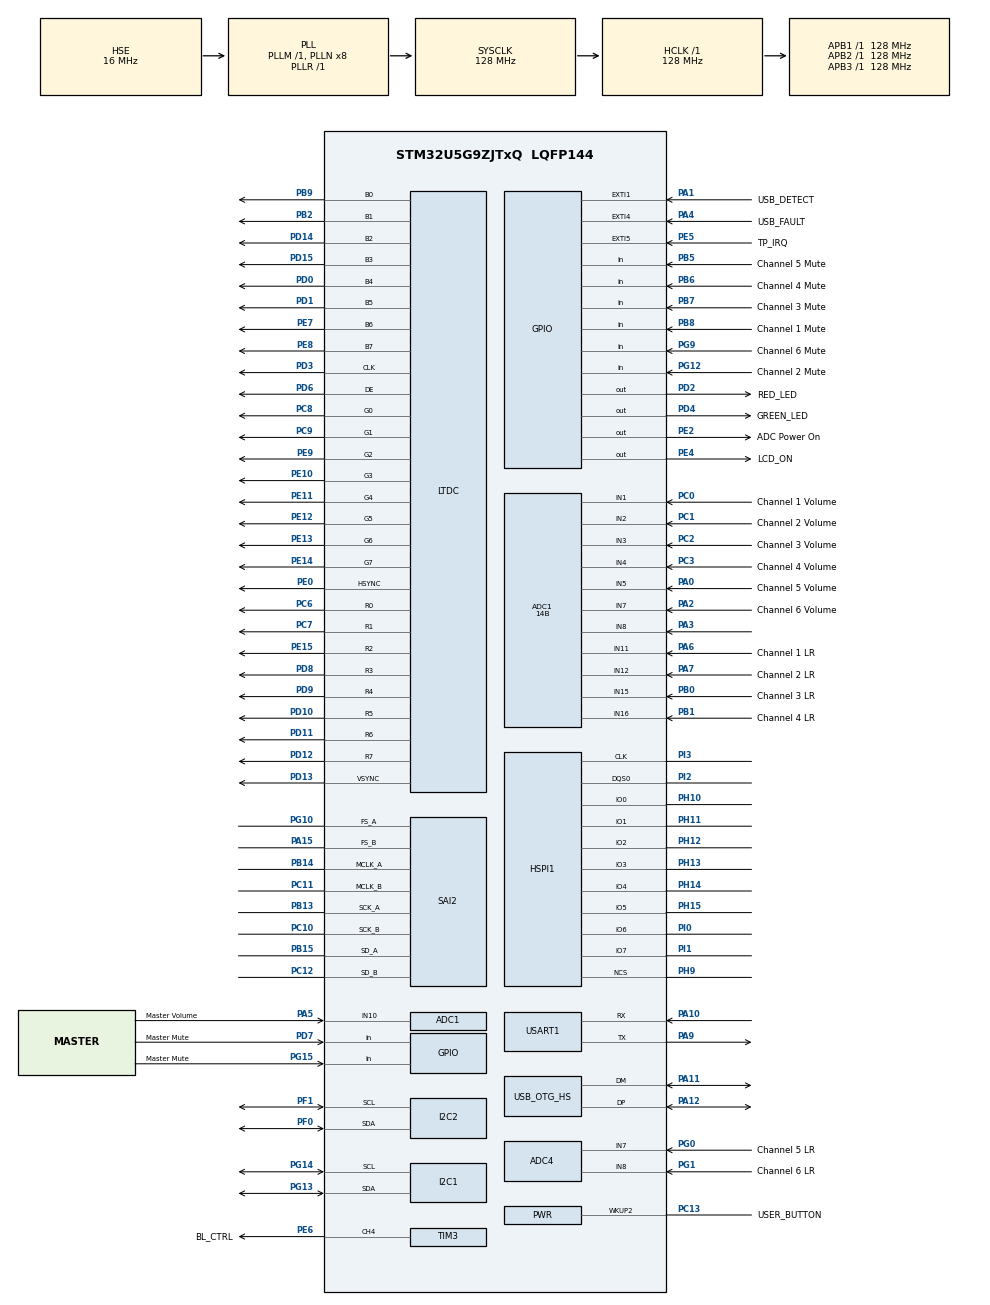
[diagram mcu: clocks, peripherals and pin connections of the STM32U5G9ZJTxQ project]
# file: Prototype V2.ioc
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ADC1.Channel-0\#ChannelRegularConversion=ADC_CHANNEL_1
ADC1.Channel-1\#ChannelRegularConversion=ADC_CHANNEL_2
ADC1.Channel-10\#ChannelRegularConversion=ADC_CHANNEL_15
ADC1.Channel-11\#ChannelRegularConversion=ADC_CHANNEL_16
ADC1.Channel-12\#ChannelRegularConversion=ADC_CHANNEL_TEMPSENSOR
ADC1.Channel-2\#ChannelRegularConversion=ADC_CHANNEL_3
ADC1.Channel-3\#ChannelRegularConversion=ADC_CHANNEL_4
ADC1.Channel-4\#ChannelRegularConversion=ADC_CHANNEL_5
ADC1.Channel-5\#ChannelRegularConversion=ADC_CHANNEL_7
ADC1.Channel-6\#ChannelRegularConversion=ADC_CHANNEL_8
ADC1.Channel-7\#ChannelRegularConversion=ADC_CHANNEL_10
ADC1.Channel-8\#ChannelRegularConversion=ADC_CHANNEL_11
ADC1.Channel-9\#ChannelRegularConversion=ADC_CHANNEL_12
ADC1.ContinuousConvMode=ENABLE
ADC1.ConversionDataManagement=ADC_CONVERSIONDATA_DMA_CIRCULAR
ADC1.DMAContinuousRequests=ENABLE
ADC1.ExternalTrigConv=ADC_EXTERNALTRIG_T15_TRGO
ADC1.LowPowerAutoWait=ENABLE
ADC1.MonitoredBy-0\#ChannelRegularConversion=__NULL
ADC1.MonitoredBy-1\#ChannelRegularConversion=__NULL
ADC1.MonitoredBy-10\#ChannelRegularConversion=__NULL
ADC1.MonitoredBy-11\#ChannelRegularConversion=__NULL
ADC1.MonitoredBy-12\#ChannelRegularConversion=__NULL
ADC1.MonitoredBy-2\#ChannelRegularConversion=__NULL
ADC1.MonitoredBy-3\#ChannelRegularConversion=__NULL
ADC1.MonitoredBy-4\#ChannelRegularConversion=__NULL
ADC1.MonitoredBy-5\#ChannelRegularConversion=__NULL
ADC1.MonitoredBy-6\#ChannelRegularConversion=__NULL
ADC1.MonitoredBy-7\#ChannelRegularConversion=__NULL
ADC1.MonitoredBy-8\#ChannelRegularConversion=__NULL
ADC1.MonitoredBy-9\#ChannelRegularConversion=__NULL
ADC1.NbrOfConversion=13
ADC1.NbrOfConversionFlag=1
ADC1.OffsetNumber-0\#ChannelRegularConversion=ADC_OFFSET_NONE
ADC1.OffsetNumber-1\#ChannelRegularConversion=ADC_OFFSET_NONE
ADC1.OffsetNumber-10\#ChannelRegularConversion=ADC_OFFSET_NONE
ADC1.OffsetNumber-11\#ChannelRegularConversion=ADC_OFFSET_NONE
ADC1.OffsetNumber-12\#ChannelRegularConversion=ADC_OFFSET_NONE
ADC1.OffsetNumber-2\#ChannelRegularConversion=ADC_OFFSET_NONE
ADC1.OffsetNumber-3\#ChannelRegularConversion=ADC_OFFSET_NONE
ADC1.OffsetNumber-4\#ChannelRegularConversion=ADC_OFFSET_NONE
ADC1.OffsetNumber-5\#ChannelRegularConversion=ADC_OFFSET_NONE
ADC1.OffsetNumber-6\#ChannelRegularConversion=ADC_OFFSET_NONE
ADC1.OffsetNumber-7\#ChannelRegularConversion=ADC_OFFSET_NONE
ADC1.OffsetNumber-8\#ChannelRegularConversion=ADC_OFFSET_NONE
ADC1.OffsetNumber-9\#ChannelRegularConversion=ADC_OFFSET_NONE
ADC1.Rank-0\#ChannelRegularConversion=1
ADC1.Rank-1\#ChannelRegularConversion=2
ADC1.Rank-10\#ChannelRegularConversion=11
ADC1.Rank-11\#ChannelRegularConversion=12
ADC1.Rank-12\#ChannelRegularConversion=13
ADC1.Rank-2\#ChannelRegularConversion=3
ADC1.Rank-3\#ChannelRegularConversion=4
ADC1.Rank-4\#ChannelRegularConversion=5
ADC1.Rank-5\#ChannelRegularConversion=6
ADC1.Rank-6\#ChannelRegularConversion=7
ADC1.Rank-7\#ChannelRegularConversion=8
ADC1.Rank-8\#ChannelRegularConversion=9
ADC1.Rank-9\#ChannelRegularConversion=10
ADC1.Resolution=ADC_RESOLUTION_14B
ADC1.SamplingTime-0\#ChannelRegularConversion=ADC_SAMPLETIME_5CYCLE
ADC1.SamplingTime-1\#ChannelRegularConversion=ADC_SAMPLETIME_5CYCLE
ADC1.SamplingTime-10\#ChannelRegularConversion=ADC_SAMPLETIME_5CYCLE
ADC1.SamplingTime-11\#ChannelRegularConversion=ADC_SAMPLETIME_5CYCLE
ADC1.SamplingTime-12\#ChannelRegularConversion=ADC_SAMPLETIME_5CYCLE
ADC1.SamplingTime-2\#ChannelRegularConversion=ADC_SAMPLETIME_5CYCLE
ADC1.SamplingTime-3\#ChannelRegularConversion=ADC_SAMPLETIME_5CYCLE
ADC1.SamplingTime-4\#ChannelRegularConversion=ADC_SAMPLETIME_5CYCLE
ADC1.SamplingTime-5\#ChannelRegularConversion=ADC_SAMPLETIME_5CYCLE
ADC1.SamplingTime-6\#ChannelRegularConversion=ADC_SAMPLETIME_5CYCLE
ADC1.SamplingTime-7\#ChannelRegularConversion=ADC_SAMPLETIME_5CYCLE
ADC1.SamplingTime-8\#ChannelRegularConversion=ADC_SAMPLETIME_5CYCLE
ADC1.SamplingTime-9\#ChannelRegularConversion=ADC_SAMPLETIME_5CYCLE
ADC1.master=1
ADC4.Channel-0\#ChannelRegularConversion=ADC_CHANNEL_7
ADC4.Channel-1\#ChannelRegularConversion=ADC_CHANNEL_8
ADC4.ContinuousConvMode=ENABLE
ADC4.DMAContinuousRequests=ENABLE
ADC4.NbrOfConversion=2
ADC4.NbrOfConversionFlag=1
ADC4.OffsetNumber-0\#ChannelRegularConversion=ADC_OFFSET_NONE
ADC4.OffsetNumber-1\#ChannelRegularConversion=ADC_OFFSET_NONE
ADC4.Rank-0\#ChannelRegularConversion=1
ADC4.Rank-1\#ChannelRegularConversion=2
ADC4.RankArg-0\#ChannelRegularConversion=ADC4_REGULAR_RANK_1
ADC4.RankArg-1\#ChannelRegularConversion=ADC4_REGULAR_RANK_2
ADC4.SamplingTime-0\#ChannelRegularConversion=ADC4_SAMPLINGTIME_COMMON_1
ADC4.SamplingTime-1\#ChannelRegularConversion=ADC4_SAMPLINGTIME_COMMON_1
ADC4.SelectedChannel=ADC_CHANNEL_7|ADC_CHANNEL_8
CORTEX_M33_NS.userName=CORTEX_M33
DMA2D.ColorMode=DMA2D_OUTPUT_RGB888
DMA2D.Mode=DMA2D_M2M
GPDMA1.CIRCULARMODE_GPDMACH0=ENABLE
GPDMA1.CIRCULARMODE_GPDMACH1=ENABLE
GPDMA1.CIRCULARMODE_GPDMACH3=ENABLE
GPDMA1.DATAHANDLING_GPDMACH3=NONE
GPDMA1.DESTDATAWIDTH_GPDMACH0=DMA_DEST_DATAWIDTH_HALFWORD
GPDMA1.DESTDATAWIDTH_GPDMACH1=DMA_DEST_DATAWIDTH_WORD
GPDMA1.DESTDATAWIDTH_GPDMACH2=DMA_DEST_DATAWIDTH_HALFWORD
GPDMA1.DESTDATAWIDTH_GPDMACH3=DMA_DEST_DATAWIDTH_WORD
GPDMA1.DESTINC_GPDMACH0=DMA_DINC_INCREMENTED
GPDMA1.DESTINC_GPDMACH1=DMA_DINC_INCREMENTED
GPDMA1.DESTINC_GPDMACH2=DMA_DINC_INCREMENTED
GPDMA1.DIRECTION_GPDMACH3=DMA_MEMORY_TO_PERIPH
GPDMA1.DMAHANDLE_GPDMACH3=hdmatx
GPDMA1.IPHANDLE_GPDMACH0-SIMPLEREQUEST_GPDMACH0=__NULL
GPDMA1.IPHANDLE_GPDMACH1-SIMPLEREQUEST_GPDMACH1=__NULL
GPDMA1.IPHANDLE_GPDMACH2-SIMPLEREQUEST_GPDMACH2=__NULL
GPDMA1.IPHANDLE_GPDMACH3-SIMPLEREQUEST_GPDMACH3=__NULL
GPDMA1.PRIORITY_LL_CIRCULAR_GPDMACH1=DMA_LOW_PRIORITY_MID_WEIGHT
GPDMA1.PRIORITY_LL_CIRCULAR_GPDMACH3=DMA_LOW_PRIORITY_HIGH_WEIGHT
GPDMA1.REQUEST_GPDMACH0=GPDMA1_REQUEST_ADC1
GPDMA1.REQUEST_GPDMACH1=GPDMA1_REQUEST_SAI2_B
GPDMA1.REQUEST_GPDMACH2=GPDMA1_REQUEST_ADC4
GPDMA1.REQUEST_GPDMACH3=GPDMA1_REQUEST_SAI2_A
GPDMA1.SRCDATAWIDTH_GPDMACH0=DMA_SRC_DATAWIDTH_HALFWORD
GPDMA1.SRCDATAWIDTH_GPDMACH1=DMA_SRC_DATAWIDTH_WORD
GPDMA1.SRCDATAWIDTH_GPDMACH2=DMA_SRC_DATAWIDTH_HALFWORD
GPDMA1.SRCDATAWIDTH_GPDMACH3=DMA_SRC_DATAWIDTH_WORD
GPDMA1.SRCINC_GPDMACH1=DMA_SINC_FIXED
GPDMA1.SRCINC_GPDMACH3=DMA_SINC_INCREMENTED
GPDMA1.TRANSFERALLOCATEDPORTDEST_GPDMACH0=DMA_DEST_ALLOCATED_PORT1
GPDMA1.TRIGGERPOLARITY_GPDMACH0=DMA_TRIG_POLARITY_RISING
GPDMA1.TRIGGERSELECTION_GPDMACH0=GPDMA1_TRIGGER_TIM15_TRGO
HSPI1.ChipSelectBoundary=HAL_XSPI_BONDARYOF_NONE
HSPI1.ChipSelectHighTimeCycle=2
HSPI1.FifoThresholdByte=4
HSPI1.MemorySize=HAL_XSPI_SIZE_1GB
HSPI1.MemoryType=HAL_XSPI_MEMTYPE_MACRONIX
I2C1.Timing=0x20A0C4DF
I2C2.Timing=0x20A0C4DF
LTDC.ActiveH=480
LTDC.ActiveW=800
LTDC.Alpha_L0=255
LTDC.BlendingFactor1_L0=LTDC_BLENDING_FACTOR1_PAxCA
LTDC.BlendingFactor2_L0=LTDC_BLENDING_FACTOR2_PAxCA
LTDC.HBP=8
LTDC.HFP=8
LTDC.HSync=4
LTDC.Layers=0
LTDC.PCPolarity=LTDC_PCPOLARITY_IPC
LTDC.PixelFormat_L0=LTDC_PIXEL_FORMAT_RGB888
LTDC.VBP=8
LTDC.VFP=8
LTDC.WindowX1_L0=800
LTDC.WindowY1_L0=480
Mcu.Family=STM32U5
Mcu.Name=STM32U5G9ZJTxQ
Mcu.Package=LQFP144
NVIC.ADC1_2_IRQn=true\:0\:0\:false\:false\:true\:true\:true\:true
NVIC.EXTI1_IRQn=true\:0\:0\:false\:false\:true\:true\:true\:true
NVIC.EXTI4_IRQn=true\:0\:0\:false\:false\:true\:true\:true\:true
NVIC.EXTI5_IRQn=true\:0\:0\:false\:false\:true\:true\:true\:true
NVIC.GPDMA1_Channel0_IRQn=true\:0\:0\:false\:false\:true\:false\:true\:true
NVIC.GPDMA1_Channel1_IRQn=true\:0\:0\:false\:false\:true\:false\:true\:true
NVIC.GPDMA1_Channel2_IRQn=true\:0\:0\:false\:false\:true\:false\:true\:true
NVIC.GPDMA1_Channel3_IRQn=true\:0\:0\:false\:false\:true\:false\:true\:true
NVIC.I2C2_ER_IRQn=true\:0\:0\:false\:false\:true\:true\:true\:false
NVIC.I2C2_EV_IRQn=true\:0\:0\:false\:false\:true\:true\:true\:true
NVIC.LTDC_IRQn=true\:0\:0\:false\:false\:true\:true\:true\:true
NVIC.PriorityGroup=NVIC_PRIORITYGROUP_4
NVIC.USART1_IRQn=true\:0\:0\:false\:false\:true\:true\:true\:true
PA0.GPIO_Label=Channel 5 Volume
PA0.Mode=IN5-Single-Ended
PA0.Signal=ADC1_IN5
PA1.GPIO_Label=USB_DETECT
PA1.GPIO_ModeDefaultEXTI=GPIO_MODE_IT_RISING_FALLING
PA1.Signal=GPXTI1
PA10.Mode=Asynchronous
PA10.Signal=USART1_RX
PA11.Mode=Internal_Phy_Device
PA11.Signal=USB_OTG_HS_DM
PA12.Mode=Internal_Phy_Device
PA12.Signal=USB_OTG_HS_DP
PA13\ (JTMS/SWDIO).Mode=Trace_Asynchronous_SW
PA13\ (JTMS/SWDIO).Signal=DEBUG_JTMS-SWDIO
PA14\ (JTCK/SWCLK).Mode=Trace_Asynchronous_SW
PA14\ (JTCK/SWCLK).Signal=DEBUG_JTCK-SWCLK
PA15\ (JTDI).GPIO_Speed=GPIO_SPEED_FREQ_VERY_HIGH
PA15\ (JTDI).Mode=SAI_B_MasterWithClock
PA15\ (JTDI).Signal=SAI2_FS_B
PA2.GPIO_Label=Channel 6 Volume
PA2.Mode=IN7-Single-Ended
PA2.Signal=ADC1_IN7
PA3.Mode=IN8-Single-Ended
PA3.Signal=ADC1_IN8
PA4.GPIO_Label=USB_FAULT
PA4.GPIO_ModeDefaultEXTI=GPIO_MODE_IT_FALLING
PA4.GPIO_PuPd=GPIO_PULLUP
PA4.Signal=GPXTI4
PA5.GPIO_Label=Master Volume
PA5.Mode=IN10-Single-Ended
PA5.Signal=ADC1_IN10
PA6.GPIO_Label=Channel 1 LR
PA6.Mode=IN11-Single-Ended
PA6.Signal=ADC1_IN11
PA7.GPIO_Label=Channel 2 LR
PA7.Mode=IN12-Single-Ended
PA7.Signal=ADC1_IN12
PA9.Mode=Asynchronous
PA9.Signal=USART1_TX
PB0.GPIO_Label=Channel 3 LR
PB0.Mode=IN15-Single-Ended
PB0.Signal=ADC1_IN15
PB1.GPIO_Label=Channel 4 LR
PB1.Mode=IN16-Single-Ended
PB1.Signal=ADC1_IN16
PB13.Mode=SAI_A_MasterWithClock
PB13.Signal=SAI2_SCK_A
PB14.GPIO_Speed=GPIO_SPEED_FREQ_VERY_HIGH
PB14.Mode=SAI_A_MasterWithClock
PB14.Signal=SAI2_MCLK_A
PB15.Mode=SAI_A_MasterWithClock
PB15.Signal=SAI2_SD_A
PB2.Mode=RGB888
PB2.Signal=LTDC_B1
PB3\ (JTDO/TRACESWO).Mode=Trace_Asynchronous_SW
PB3\ (JTDO/TRACESWO).Signal=DEBUG_JTDO-SWO
PB5.GPIO_Label=Channel 5 Mute
PB5.Signal=GPIO_Input
PB6.GPIO_Label=Channel 4 Mute
PB6.Signal=GPIO_Input
PB7.GPIO_Label=Channel 3 Mute
PB7.Signal=GPIO_Input
PB8.GPIO_Label=Channel 1 Mute
PB8.Signal=GPIO_Input
PB9.Mode=RGB888
PB9.Signal=LTDC_B0
PC0.GPIO_Label=Channel 1 Volume
PC0.Mode=IN1-Single-Ended
PC0.Signal=ADC1_IN1
PC1.GPIO_Label=Channel 2 Volume
PC1.Mode=IN2-Single-Ended
PC1.Signal=ADC1_IN2
PC10.GPIO_PuPd=GPIO_NOPULL
PC10.GPIO_Speed=GPIO_SPEED_FREQ_VERY_HIGH
PC10.Mode=SAI_B_MasterWithClock
PC10.Signal=SAI2_SCK_B
PC11.Mode=SAI_B_MasterWithClock
PC11.Signal=SAI2_MCLK_B
PC12.Mode=SAI_B_MasterWithClock
PC12.Signal=SAI2_SD_B
PC13.GPIO_Label=USER_BUTTON
PC13.Mode=WakeUp2
PC13.Signal=PWR_WKUP2
PC14-OSC32_IN\ (PC14).Mode=LSE-External-Oscillator
PC14-OSC32_IN\ (PC14).Signal=RCC_OSC32_IN
PC15-OSC32_OUT\ (PC15).Mode=LSE-External-Oscillator
PC15-OSC32_OUT\ (PC15).Signal=RCC_OSC32_OUT
PC2.GPIO_Label=Channel 3 Volume
PC2.Mode=IN3-Single-Ended
PC2.Signal=ADC1_IN3
PC3.GPIO_Label=Channel 4 Volume
PC3.Mode=IN4-Single-Ended
PC3.Signal=ADC1_IN4
PC6.Mode=RGB888
PC6.Signal=LTDC_R0
PC7.Mode=RGB888
PC7.Signal=LTDC_R1
PC8.Mode=RGB888
PC8.Signal=LTDC_G0
PC9.Mode=RGB888
PC9.Signal=LTDC_G1
PD0.Mode=RGB888
PD0.Signal=LTDC_B4
PD1.Mode=RGB888
PD1.Signal=LTDC_B5
PD10.Mode=RGB888
PD10.Signal=LTDC_R5
PD11.Mode=RGB888
PD11.Signal=LTDC_R6
PD12.Mode=RGB888
PD12.Signal=LTDC_R7
PD13.Mode=RGB888
PD13.Signal=LTDC_VSYNC
PD14.Mode=RGB888
PD14.Signal=LTDC_B2
PD15.Mode=RGB888
PD15.Signal=LTDC_B3
PD2.GPIO_Label=RED_LED
PD2.Signal=GPIO_Output
PD3.Mode=RGB888
PD3.Signal=LTDC_CLK
PD4.GPIO_Label=GREEN_LED
PD4.Signal=GPIO_Output
PD6.Mode=RGB888
PD6.Signal=LTDC_DE
PD7.GPIO_Label=Master Mute
PD7.Signal=GPIO_Input
PD8.Mode=RGB888
PD8.Signal=LTDC_R3
PD9.Mode=RGB888
PD9.Signal=LTDC_R4
PE0.Mode=RGB888
PE0.Signal=LTDC_HSYNC
PE10.Mode=RGB888
PE10.Signal=LTDC_G3
PE11.Mode=RGB888
PE11.Signal=LTDC_G4
PE12.Mode=RGB888
PE12.Signal=LTDC_G5
PE13.Mode=RGB888
PE13.Signal=LTDC_G6
PE14.Mode=RGB888
PE14.Signal=LTDC_G7
PE15.Mode=RGB888
PE15.Signal=LTDC_R2
PE2.GPIO_Label=ADC Power On
PE2.Signal=GPIO_Output
PE4.GPIO_Label=LCD_ON
PE4.PinState=GPIO_PIN_SET
PE4.Signal=GPIO_Output
PE5.GPIO_Label=TP_IRQ
PE5.Signal=GPXTI5
PE6.GPIO_Label=BL_CTRL
PE6.Signal=S_TIM3_CH4
PE7.Mode=RGB888
PE7.Signal=LTDC_B6
PE8.Mode=RGB888
PE8.Signal=LTDC_B7
PE9.Mode=RGB888
PE9.Signal=LTDC_G2
PF0.Mode=I2C
PF0.Signal=I2C2_SDA
PF1.Mode=I2C
PF1.Signal=I2C2_SCL
PG0.GPIO_Label=Channel 5 LR
PG0.Mode=IN7
PG0.Signal=ADC4_IN7
PG1.GPIO_Label=Channel 6 LR
PG1.Mode=IN8
PG1.Signal=ADC4_IN8
PG10.Mode=SAI_A_MasterWithClock
PG10.Signal=SAI2_FS_A
PG12.GPIO_Label=Channel 2 Mute
PG12.Signal=GPIO_Input
PG13.Mode=I2C
PG13.Signal=I2C1_SDA
PG14.Mode=I2C
PG14.Signal=I2C1_SCL
PG15.GPIO_Label=Master Mute
PG15.Signal=GPIO_Input
PG9.GPIO_Label=Channel 6 Mute
PG9.Signal=GPIO_Input
PH0-OSC_IN\ (PH0).Mode=HSE-External-Oscillator
PH0-OSC_IN\ (PH0).Signal=RCC_OSC_IN
PH1-OSC_OUT\ (PH1).Mode=HSE-External-Oscillator
PH1-OSC_OUT\ (PH1).Signal=RCC_OSC_OUT
PH10.Mode=octo_mode
PH10.Signal=HSPI1_IO0
PH11.Mode=octo_mode
PH11.Signal=HSPI1_IO1
PH12.Mode=octo_mode
PH12.Signal=HSPI1_IO2
PH13.Mode=octo_mode
PH13.Signal=HSPI1_IO3
PH14.Mode=octo_mode
PH14.Signal=HSPI1_IO4
PH15.Mode=octo_mode
PH15.Signal=HSPI1_IO5
PH9.Mode=octo_mode
PH9.Signal=HSPI1_NCS
PI0.Mode=octo_mode
PI0.Signal=HSPI1_IO6
PI1.Mode=octo_mode
PI1.Signal=HSPI1_IO7
PI2.Mode=octo_mode
PI2.Signal=HSPI1_DQS0
PI3.Mode=octo_mode
PI3.Signal=HSPI1_CLK
PWR.PowerMode=PWR_SMPS_SUPPLY
ProjectManager.HeapSize=0x400
ProjectManager.StackSize=0x800
ProjectManager.TargetToolchain=STM32CubeIDE
RCC.ADCFreq_Value=16000000
RCC.AHBFreq_Value=128000000
RCC.APB1Freq_Value=128000000
RCC.APB1TimFreq_Value=128000000
RCC.APB2Freq_Value=128000000
RCC.APB2TimFreq_Value=128000000
RCC.APB3Freq_Value=128000000
RCC.CortexFreq_Value=128000000
RCC.EPOD_VALUE=16000000
RCC.HCLKFreq_Value=128000000
RCC.HSE_VALUE=16000000
RCC.HSI48_VALUE=48000000
RCC.HSI_VALUE=16000000
RCC.HSPICLockSelection=RCC_HSPICLKSOURCE_PLL2
RCC.LSIDIV_VALUE=32000
RCC.LTDCCLockSelection=RCC_LTDCCLKSOURCE_PLL3
RCC.MSIClockRange=RCC_MSIRANGE_0
RCC.MSI_VALUE=48000000
RCC.PLL1P=8
RCC.PLL1R=1
RCC.PLL2FRACN=4096
RCC.PLL2N=12
RCC.PLL2Q=3
RCC.PLL2R=4
RCC.PLL2Source=RCC_PLLSOURCE_HSE
RCC.PLL3FRACN=0
RCC.PLL3M=4
RCC.PLL3N=50
RCC.PLL3R=8
RCC.PLL3Source=RCC_PLLSOURCE_HSE
RCC.PLLFRACN=0
RCC.PLLN=8
RCC.PLLSourceVirtual=RCC_PLLSOURCE_HSE
RCC.RTCClockSelection=RCC_RTCCLKSOURCE_LSE
RCC.SYSCLKFreq_VALUE=128000000
RCC.SYSCLKSource=RCC_SYSCLKSOURCE_PLLCLK
RCC.VCOOutputFreq_Value=128000000
SAI2.AudioFrequency-SAI_A_MasterWithClock=SAI_AUDIO_FREQUENCY_96K
SAI2.AudioFrequency-SAI_B_MasterWithClock=SAI_AUDIO_FREQUENCY_96K
SAI2.AudioMode-SAI_B_MasterWithClock=SAI_MODEMASTER_RX
SAI2.BasicDataSize-SAI_A_MasterWithClock=SAI_PROTOCOL_DATASIZE_24BIT
SAI2.BasicDataSize-SAI_B_MasterWithClock=SAI_PROTOCOL_DATASIZE_24BIT
SAI2.BasicProtocol-SAI_A_MasterWithClock=SAI_I2S_MSBJUSTIFIED
SAI2.BasicSlotNumber-SAI_B_MasterWithClock=8
SAI2.ErrorAudioFreq-SAI_A_MasterWithClock=1.72 %
SAI2.ErrorAudioFreq-SAI_B_MasterWithClock=1.72 %
SAI2.FIFOThreshold-SAI_A_MasterWithClock=SAI_FIFOTHRESHOLD_EMPTY
SAI2.FIFOThreshold-SAI_B_MasterWithClock=SAI_FIFOTHRESHOLD_HF
SAI2.InitProtocol-SAI_A_MasterWithClock=Enable
SAI2.InitProtocol-SAI_B_MasterWithClock=Enable
SAI2.Instance-SAI_A_MasterWithClock=SAI$Index_Block_A
SAI2.Instance-SAI_B_MasterWithClock=SAI$Index_Block_B
SAI2.MckOutput-SAI_A_MasterWithClock=SAI_MCK_OUTPUT_ENABLE
SAI2.MckOutput-SAI_B_MasterWithClock=SAI_MCK_OUTPUT_ENABLE
SAI2.RealAudioFreq-SAI_A_MasterWithClock=97.656 KHz
SAI2.RealAudioFreq-SAI_B_MasterWithClock=97.656 KHz
SAI2.TriState-SAI_A_MasterWithClock=SAI_OUTPUT_RELEASED
SAI2.VirtualMode-SAI_A_MasterWithClock=VM_MASTER
SAI2.VirtualMode-SAI_B_MasterWithClock=VM_MASTER
SAI2.VirtualProtocol-SAI_A_BASIC=VM_BASIC_PROTOCOL
SAI2.VirtualProtocol-SAI_B_BASIC=VM_BASIC_PROTOCOL
SH.S_TIM3_CH4.0=TIM3_CH4,PWM Generation4 CH4
TIM15.PeriodNoDither=49
TIM15.Prescaler=26
TIM15.TIM_MasterOutputTrigger=TIM_TRGO_UPDATE
TIM3.Channel-PWM\ Generation4\ CH4=TIM_CHANNEL_4
TIM3.OC4Preload_PWM=DISABLE
TIM3.PeriodNoDither=100
TIM3.Prescaler=160
TIM3.PulseNoDither_4=75
USART1.VirtualMode-Asynchronous=VM_ASYNC
USB_OTG_HS.VirtualMode=Device_HS
VP_ADC1_TempSens_Input.Mode=IN-TempSens
VP_DMA2D_VS_DMA2D.Mode=DMA2D_Activate
VP_GPDMA1_VS_GPDMACH0.Mode=SIMPLEREQUEST_GPDMACH0
VP_GPDMA1_VS_GPDMACH1.Mode=SIMPLEREQUEST_GPDMACH1
VP_GPDMA1_VS_GPDMACH2.Mode=SIMPLEREQUEST_GPDMACH2
VP_GPDMA1_VS_GPDMACH3.Mode=SIMPLEREQUEST_GPDMACH3
VP_ICACHE_VS_ICACHE.Mode=DirectMappedCache
VP_LPBAMQUEUE_VS_QUEUE.Mode=QUEUEMODE
VP_LPBAM_VS_SIG1.Mode=SmartRun
VP_LPBAM_VS_SIG4.Mode=LPDMA1
VP_MEMORYMAP_VS_MEMORYMAP.Mode=CurAppReg
VP_PWR_VS_LPOM.Mode=PowerOptimisation
VP_PWR_VS_SECSignals.Mode=Security/Privilege
VP_PWR_Vdda.Mode=isolationVdda
VP_RTC_VS_RTC_Activate.Mode=RTC_Enabled
VP_SAI2_VP_$IpInstance_SAIA_SAI_BASIC.Mode=SAI_A_BASIC
VP_SAI2_VP_$IpInstance_SAIB_SAI_BASIC.Mode=SAI_B_BASIC
VP_TIM15_VS_ClockSourceINT.Mode=Internal
board=STM32U5G9J-DK2

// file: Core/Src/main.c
/* USER CODE BEGIN Header */
/**
  ******************************************************************************
  * @file           : main.c
  * @brief          : Main program body
  ******************************************************************************
  * @attention
  *
  * Copyright (c) 2024 STMicroelectronics.
  * All rights reserved.
  *
  * This software is licensed under terms that can be found in the LICENSE file
  * in the root directory of this software component.
  * If no LICENSE file comes with this software, it is provided AS-IS.
  *
  ******************************************************************************
  */
/* USER CODE END Header */
#include "main.h"

/* USER CODE BEGIN Includes */
#include "math.h"
#include "stdbool.h"
/* USER CODE END Includes */

/* USER CODE BEGIN PD */
#define sampleSize 32 //System will capture specificed number of samples per channel
#define denoiseSize 1
#define gain 1
#define devAddress 0x90 //Device address of PCM6260, pre-shift
//TODO: Determine the actual array position of these values
#define c1Vol 0
#define c2Vol 1
#define c3Vol 2
#define c4Vol 3
#define c5Vol 4
#define c6Vol 5
#define masterVol 6
#define c1LR 7
#define c2LR 8
#define c3LR 9
#define c4LR 10
#define c5LR 11
#define c6LR 12

#define channelSettings 0xA6
/*
 * 7 - 0 = Microphone 1 = Line
 * 6-5 - 0d = analog differential 1d = analog single ended
 * 4 - 0d = A/C coupled 1d = D/C coupled
 * 3 - 0d low swing mode 1d high swing mode
 * 2-1 - 0d high snr 2d high cmrr
 * 0 0 - AGC disabled, 1 - AGC enabled
 */

//Struct defining a "Channel" object, which consists of a sample buffer, and various effect
//control parameters
struct channelStruct{
	uint32_t channelData[sampleSize];
	uint8_t channelNum;
	bool masterMute;
	float volume;
	float LRPan;
	bool reverbEnable;
	bool EQEnable;
	bool distortionEnable;
	float reverbStrength;
	float eqLevels[5];
	float distortionStrength;
};
/* USER CODE END PD */

/* USER CODE BEGIN PM */
#define DIM(a)	(sizeof(a)/sizeof(*a)) //Macro for determining correct TX/RX size
/* USER CODE END PM */

ADC_HandleTypeDef hadc1;
ADC_HandleTypeDef hadc4;
DMA_NodeTypeDef Node_GPDMA1_Channel0;
DMA_QListTypeDef List_GPDMA1_Channel0;
DMA_HandleTypeDef handle_GPDMA1_Channel0;
DMA_HandleTypeDef handle_GPDMA1_Channel2;

DMA2D_HandleTypeDef hdma2d;

XSPI_HandleTypeDef hxspi1;

I2C_HandleTypeDef hi2c1;
I2C_HandleTypeDef hi2c2;

LTDC_HandleTypeDef hltdc;

RTC_HandleTypeDef hrtc;

SAI_HandleTypeDef hsai_BlockA2;
SAI_HandleTypeDef hsai_BlockB2;
DMA_NodeTypeDef Node_GPDMA1_Channel3;
DMA_QListTypeDef List_GPDMA1_Channel3;
DMA_HandleTypeDef handle_GPDMA1_Channel3;
DMA_NodeTypeDef Node_GPDMA1_Channel1;
DMA_QListTypeDef List_GPDMA1_Channel1;
DMA_HandleTypeDef handle_GPDMA1_Channel1;

TIM_HandleTypeDef htim3;
TIM_HandleTypeDef htim15;

UART_HandleTypeDef huart1;

PCD_HandleTypeDef hpcd_USB_OTG_HS;

/* USER CODE BEGIN PV */

uint16_t adcGroup1[13] = {0}; //buffer for all ADC values connected to ADC1(volume and LR pots)
uint16_t adcGroup4[2] = {0}; //buffer for all ADC Values connected to ADC4(volume and LR pots)
uint32_t pcmData[sampleSize  * 8] = {0}; //Buffer for 8 channels of audio data
int32_t dacData[sampleSize * 2] = {0};
float ch1Vol = 0;

//contains all instructions for configuring PCM6260
static uint8_t pcm6260Config[][2] =
{
		{0x00, 0x00},//Set page to 0
		{0x02, 0x81},//Set to awake
		{0x28,0x10},//Settings reset
		{0x3C,channelSettings}, //config channels
		{0x46,channelSettings},
		{0x4B,channelSettings},
		{0x50,channelSettings},
		{0x55,channelSettings},
		{0x3B, 0x70}, //
		{0x73,0xFE}, //Enable Input Channels
		{0x74, 0xFE}, //Enable ASI output
		{0x3B, 0xF0}, //Config MicBias 9v
		{0x75, 0xE0} //enable Micbias, PLL
};

struct channelStruct channels[6] = {0}; //Creates a blank channelStruct array
/* USER CODE END PV */

void SystemClock_Config(void);
void PeriphCommonClock_Config(void);
static void SystemPower_Config(void);
static void MX_GPIO_Init(void);
static void MX_GPDMA1_Init(void);
static void MX_DMA2D_Init(void);
static void MX_HSPI1_Init(void);
static void MX_I2C2_Init(void);
static void MX_ICACHE_Init(void);
static void MX_LTDC_Init(void);
static void MX_RTC_Init(void);
static void MX_TIM3_Init(void);
static void MX_ADC1_Init(void);
static void MX_USART1_UART_Init(void);
static void MX_SAI2_Init(void);
static void MX_ADC4_Init(void);
static void MX_I2C1_Init(void);
static void MX_USB_OTG_HS_PCD_Init(void);
static void MX_TIM15_Init(void);
/* USER CODE BEGIN PFP */
static uint16_t getAverageADC(uint16_t);
/* USER CODE END PFP */

int main(void)
{

  /* MCU Configuration--------------------------------------------------------*/

  /* Reset of all peripherals, Initializes the Flash interface and the Systick. */
  HAL_Init();

  /* Configure the system clock */
  SystemClock_Config();

  /* Configure the peripherals common clocks */
  PeriphCommonClock_Config();

  /* Configure the System Power */
  SystemPower_Config();

  /* Initialize all configured peripherals */
  MX_GPIO_Init();
  MX_GPDMA1_Init();
  MX_DMA2D_Init();
  MX_HSPI1_Init();
  MX_I2C2_Init();
  MX_ICACHE_Init();
  MX_LTDC_Init();
  MX_RTC_Init();
  MX_TIM3_Init();
  MX_ADC1_Init();
  MX_USART1_UART_Init();
  MX_SAI2_Init();
  MX_ADC4_Init();
  MX_I2C1_Init();
  MX_USB_OTG_HS_PCD_Init();
  MX_TIM15_Init();
  /* USER CODE BEGIN 2 */
  HAL_ADC_Start_DMA(&hadc1, (uint16_t*)adcGroup1, DIM(adcGroup1)); //Begins DMA transfer for first ADC
  HAL_ADC_Start_DMA(&hadc4, (uint16_t*)adcGroup4, DIM(adcGroup4)); //begins DMA transfer for fourth ADC
  HAL_TIM_Base_Start(&htim15);

  HAL_Delay(2000);
  HAL_GPIO_WritePin(ADC_Power_On_GPIO_Port, ADC_Power_On_Pin, GPIO_PIN_SET); //Powers SHDNZ High to enable PCM6260
  HAL_Delay(2000);

  //Transmits each instruction sequentially from pcm6260Config array
  for(int i = 0; i < sizeof(pcm6260Config); i++)
  {
	  HAL_I2C_Master_Transmit(&hi2c1, devAddress, pcm6260Config[i], DIM(pcm6260Config[i]), 100);
	  HAL_Delay(100);
  }

  HAL_Delay(100);
  HAL_SAI_Receive_DMA(&hsai_BlockB2, (uint8_t*)pcmData, DIM(pcmData)); //Begins DMA transfer for PCM6260
  HAL_SAI_Transmit_DMA(&hsai_BlockA2, (uint8_t*)dacData, DIM(dacData));

  //Populates each channel in the channels struct with initializer values
  for(int i = 0; i < sizeof(channels); i++)
  {
	  for(int s = 0; s < sizeof(channels[i].channelData); s++)
	  {
		  channels[i].channelData[s] = 0;
	  }
	  channels[i].channelNum = i;
	  channels[i].volume = 0.0;
	  channels[i].LRPan = 0.0;
	  channels[i].reverbEnable = false;
	  channels[i].EQEnable = false;
	  channels[i].distortionEnable = false;
	  channels[i].reverbStrength = 0.0;
	  for(int r = 0; r < sizeof(channels[i].eqLevels);r++)
	  {
		  channels[i].eqLevels[r] = 0.0;
	  }
	  channels[i].distortionStrength = 0.0;
  }
  /* USER CODE END 2 */

  /* Infinite loop */
  /* USER CODE BEGIN WHILE */
while (1)
  {

	  //Reads and sets the position of each volume slider
	  channels[0].volume = (float)(adcGroup1[c1Vol]);
	  channels[1].volume = (float)(adcGroup1[c2Vol]);
	  channels[2].volume = (float)(adcGroup1[c3Vol]);
	  channels[3].volume = (float)(adcGroup1[c4Vol]);
	  channels[4].volume = (float)(adcGroup1[c5Vol]);
	  channels[5].volume = (float)(adcGroup1[c6Vol]);

	  //Reads and sets the position of each LR Knob
	  channels[0].LRPan = (float)(adcGroup1[c1LR]);
	  channels[1].LRPan = (float)(adcGroup1[c2LR]);
	  channels[2].LRPan = (float)(adcGroup1[c3LR]);
	  channels[3].LRPan = (float)(adcGroup1[c4LR]);
	  channels[4].LRPan = (float)(adcGroup4[c5LR]);
	  channels[5].LRPan = (float)(adcGroup4[c6LR]);
    /* USER CODE END WHILE */

  }
}

void SystemClock_Config(void)
{
  RCC_OscInitTypeDef RCC_OscInitStruct = {0};
  RCC_ClkInitTypeDef RCC_ClkInitStruct = {0};

  /** Configure the main internal regulator output voltage
  */
  if (HAL_PWREx_ControlVoltageScaling(PWR_REGULATOR_VOLTAGE_SCALE1) != HAL_OK)
  {
    Error_Handler();
  }

  /** Configure LSE Drive Capability
  */
  HAL_PWR_EnableBkUpAccess();
  __HAL_RCC_LSEDRIVE_CONFIG(RCC_LSEDRIVE_LOW);

  /** Initializes the CPU, AHB and APB buses clocks
  */
  RCC_OscInitStruct.OscillatorType = RCC_OSCILLATORTYPE_HSI|RCC_OSCILLATORTYPE_HSE
                              |RCC_OSCILLATORTYPE_LSE;
  RCC_OscInitStruct.HSEState = RCC_HSE_ON;
  RCC_OscInitStruct.LSEState = RCC_LSE_ON;
  RCC_OscInitStruct.HSIState = RCC_HSI_ON;
  RCC_OscInitStruct.HSICalibrationValue = RCC_HSICALIBRATION_DEFAULT;
  RCC_OscInitStruct.PLL.PLLState = RCC_PLL_ON;
  RCC_OscInitStruct.PLL.PLLSource = RCC_PLLSOURCE_HSE;
  RCC_OscInitStruct.PLL.PLLMBOOST = RCC_PLLMBOOST_DIV1;
  RCC_OscInitStruct.PLL.PLLM = 1;
  RCC_OscInitStruct.PLL.PLLN = 8;
  RCC_OscInitStruct.PLL.PLLP = 8;
  RCC_OscInitStruct.PLL.PLLQ = 2;
  RCC_OscInitStruct.PLL.PLLR = 1;
  RCC_OscInitStruct.PLL.PLLRGE = RCC_PLLVCIRANGE_1;
  RCC_OscInitStruct.PLL.PLLFRACN = 0;
  if (HAL_RCC_OscConfig(&RCC_OscInitStruct) != HAL_OK)
  {
    Error_Handler();
  }

  /** Initializes the CPU, AHB and APB buses clocks
  */
  RCC_ClkInitStruct.ClockType = RCC_CLOCKTYPE_HCLK|RCC_CLOCKTYPE_SYSCLK
                              |RCC_CLOCKTYPE_PCLK1|RCC_CLOCKTYPE_PCLK2
                              |RCC_CLOCKTYPE_PCLK3;
  RCC_ClkInitStruct.SYSCLKSource = RCC_SYSCLKSOURCE_PLLCLK;
  RCC_ClkInitStruct.AHBCLKDivider = RCC_SYSCLK_DIV1;
  RCC_ClkInitStruct.APB1CLKDivider = RCC_HCLK_DIV1;
  RCC_ClkInitStruct.APB2CLKDivider = RCC_HCLK_DIV1;
  RCC_ClkInitStruct.APB3CLKDivider = RCC_HCLK_DIV1;

  if (HAL_RCC_ClockConfig(&RCC_ClkInitStruct, FLASH_LATENCY_3) != HAL_OK)
  {
    Error_Handler();
  }
}

void PeriphCommonClock_Config(void)
{
  RCC_PeriphCLKInitTypeDef PeriphClkInit = {0};

  /** Initializes the common periph clock
  */
  PeriphClkInit.PeriphClockSelection = RCC_PERIPHCLK_HSPI|RCC_PERIPHCLK_SAI2;
  PeriphClkInit.Sai2ClockSelection = RCC_SAI2CLKSOURCE_PLL2;
  PeriphClkInit.HspiClockSelection = RCC_HSPICLKSOURCE_PLL2;
  PeriphClkInit.PLL2.PLL2Source = RCC_PLLSOURCE_HSE;
  PeriphClkInit.PLL2.PLL2M = 1;
  PeriphClkInit.PLL2.PLL2N = 12;
  PeriphClkInit.PLL2.PLL2P = 2;
  PeriphClkInit.PLL2.PLL2Q = 3;
  PeriphClkInit.PLL2.PLL2R = 4;
  PeriphClkInit.PLL2.PLL2RGE = RCC_PLLVCIRANGE_1;
  PeriphClkInit.PLL2.PLL2FRACN = 4096;
  PeriphClkInit.PLL2.PLL2ClockOut = RCC_PLL2_DIVP|RCC_PLL2_DIVQ;
  if (HAL_RCCEx_PeriphCLKConfig(&PeriphClkInit) != HAL_OK)
  {
    Error_Handler();
  }
}

/**
  * @brief Power Configuration
  * @retval None
  */
static void SystemPower_Config(void)
{
  HAL_PWREx_EnableVddIO2();

  /*
   * Switch to SMPS regulator instead of LDO
   */
  if (HAL_PWREx_ConfigSupply(PWR_SMPS_SUPPLY) != HAL_OK)
  {
    Error_Handler();
  }
}

static void MX_ADC1_Init(void)
{

  ADC_ChannelConfTypeDef sConfig = {0};

  /** Common config
  */
  hadc1.Instance = ADC1;
  hadc1.Init.ClockPrescaler = ADC_CLOCK_ASYNC_DIV1;
  hadc1.Init.Resolution = ADC_RESOLUTION_14B;
  hadc1.Init.GainCompensation = 0;
  hadc1.Init.DataAlign = ADC_DATAALIGN_RIGHT;
  hadc1.Init.ScanConvMode = ADC_SCAN_ENABLE;
  hadc1.Init.EOCSelection = ADC_EOC_SINGLE_CONV;
  hadc1.Init.LowPowerAutoWait = ENABLE;
  hadc1.Init.ContinuousConvMode = ENABLE;
  hadc1.Init.NbrOfConversion = 13;
  hadc1.Init.DiscontinuousConvMode = DISABLE;
  hadc1.Init.ExternalTrigConv = ADC_EXTERNALTRIG_T15_TRGO;
  hadc1.Init.ExternalTrigConvEdge = ADC_EXTERNALTRIGCONVEDGE_RISING;
  hadc1.Init.DMAContinuousRequests = ENABLE;
  hadc1.Init.TriggerFrequencyMode = ADC_TRIGGER_FREQ_HIGH;
  hadc1.Init.Overrun = ADC_OVR_DATA_PRESERVED;
  hadc1.Init.LeftBitShift = ADC_LEFTBITSHIFT_NONE;
  hadc1.Init.ConversionDataManagement = ADC_CONVERSIONDATA_DMA_CIRCULAR;
  hadc1.Init.OversamplingMode = DISABLE;
  if (HAL_ADC_Init(&hadc1) != HAL_OK)
  {
    Error_Handler();
  }

  /** Configure Regular Channel
  */
  sConfig.Channel = ADC_CHANNEL_1;
  sConfig.Rank = ADC_REGULAR_RANK_1;
  sConfig.SamplingTime = ADC_SAMPLETIME_5CYCLE;
  sConfig.SingleDiff = ADC_SINGLE_ENDED;
  sConfig.OffsetNumber = ADC_OFFSET_NONE;
  sConfig.Offset = 0;
  if (HAL_ADC_ConfigChannel(&hadc1, &sConfig) != HAL_OK)
  {
    Error_Handler();
  }

  /** Configure Regular Channel
  */
  sConfig.Channel = ADC_CHANNEL_2;
  sConfig.Rank = ADC_REGULAR_RANK_2;
  if (HAL_ADC_ConfigChannel(&hadc1, &sConfig) != HAL_OK)
  {
    Error_Handler();
  }

  /** Configure Regular Channel
  */
  sConfig.Channel = ADC_CHANNEL_3;
  sConfig.Rank = ADC_REGULAR_RANK_3;
  if (HAL_ADC_ConfigChannel(&hadc1, &sConfig) != HAL_OK)
  {
    Error_Handler();
  }

  /** Configure Regular Channel
  */
  sConfig.Channel = ADC_CHANNEL_4;
  sConfig.Rank = ADC_REGULAR_RANK_4;
  if (HAL_ADC_ConfigChannel(&hadc1, &sConfig) != HAL_OK)
  {
    Error_Handler();
  }

  /** Configure Regular Channel
  */
  sConfig.Channel = ADC_CHANNEL_5;
  sConfig.Rank = ADC_REGULAR_RANK_5;
  if (HAL_ADC_ConfigChannel(&hadc1, &sConfig) != HAL_OK)
  {
    Error_Handler();
  }

  /** Configure Regular Channel
  */
  sConfig.Channel = ADC_CHANNEL_7;
  sConfig.Rank = ADC_REGULAR_RANK_6;
  if (HAL_ADC_ConfigChannel(&hadc1, &sConfig) != HAL_OK)
  {
    Error_Handler();
  }

  /** Configure Regular Channel
  */
  sConfig.Channel = ADC_CHANNEL_8;
  sConfig.Rank = ADC_REGULAR_RANK_7;
  if (HAL_ADC_ConfigChannel(&hadc1, &sConfig) != HAL_OK)
  {
    Error_Handler();
  }

  /** Configure Regular Channel
  */
  sConfig.Channel = ADC_CHANNEL_10;
  sConfig.Rank = ADC_REGULAR_RANK_8;
  if (HAL_ADC_ConfigChannel(&hadc1, &sConfig) != HAL_OK)
  {
    Error_Handler();
  }

  /** Configure Regular Channel
  */
  sConfig.Channel = ADC_CHANNEL_11;
  sConfig.Rank = ADC_REGULAR_RANK_9;
  if (HAL_ADC_ConfigChannel(&hadc1, &sConfig) != HAL_OK)
  {
    Error_Handler();
  }

  /** Configure Regular Channel
  */
  sConfig.Channel = ADC_CHANNEL_12;
  sConfig.Rank = ADC_REGULAR_RANK_10;
  if (HAL_ADC_ConfigChannel(&hadc1, &sConfig) != HAL_OK)
  {
    Error_Handler();
  }

  /** Configure Regular Channel
  */
  sConfig.Channel = ADC_CHANNEL_15;
  sConfig.Rank = ADC_REGULAR_RANK_11;
  if (HAL_ADC_ConfigChannel(&hadc1, &sConfig) != HAL_OK)
  {
    Error_Handler();
  }

  /** Configure Regular Channel
  */
  sConfig.Channel = ADC_CHANNEL_16;
  sConfig.Rank = ADC_REGULAR_RANK_12;
  if (HAL_ADC_ConfigChannel(&hadc1, &sConfig) != HAL_OK)
  {
    Error_Handler();
  }

  /** Configure Regular Channel
  */
  sConfig.Channel = ADC_CHANNEL_TEMPSENSOR;
  sConfig.Rank = ADC_REGULAR_RANK_13;
  if (HAL_ADC_ConfigChannel(&hadc1, &sConfig) != HAL_OK)
  {
    Error_Handler();
  }

}

static void MX_ADC4_Init(void)
{

  ADC_ChannelConfTypeDef sConfig = {0};

  /** Common config
  */
  hadc4.Instance = ADC4;
  hadc4.Init.ClockPrescaler = ADC_CLOCK_ASYNC_DIV1;
  hadc4.Init.Resolution = ADC_RESOLUTION_12B;
  hadc4.Init.DataAlign = ADC_DATAALIGN_RIGHT;
  hadc4.Init.ScanConvMode = ADC4_SCAN_ENABLE;
  hadc4.Init.EOCSelection = ADC_EOC_SINGLE_CONV;
  hadc4.Init.LowPowerAutoPowerOff = ADC_LOW_POWER_NONE;
  hadc4.Init.LowPowerAutoWait = DISABLE;
  hadc4.Init.ContinuousConvMode = ENABLE;
  hadc4.Init.NbrOfConversion = 2;
  hadc4.Init.ExternalTrigConv = ADC_SOFTWARE_START;
  hadc4.Init.ExternalTrigConvEdge = ADC_EXTERNALTRIGCONVEDGE_NONE;
  hadc4.Init.DMAContinuousRequests = ENABLE;
  hadc4.Init.TriggerFrequencyMode = ADC_TRIGGER_FREQ_LOW;
  hadc4.Init.Overrun = ADC_OVR_DATA_PRESERVED;
  hadc4.Init.SamplingTimeCommon1 = ADC4_SAMPLETIME_1CYCLE_5;
  hadc4.Init.SamplingTimeCommon2 = ADC4_SAMPLETIME_1CYCLE_5;
  hadc4.Init.OversamplingMode = DISABLE;
  if (HAL_ADC_Init(&hadc4) != HAL_OK)
  {
    Error_Handler();
  }

  /** Configure Regular Channel
  */
  sConfig.Channel = ADC_CHANNEL_7;
  sConfig.Rank = ADC4_REGULAR_RANK_1;
  sConfig.SamplingTime = ADC4_SAMPLINGTIME_COMMON_1;
  sConfig.OffsetNumber = ADC_OFFSET_NONE;
  sConfig.Offset = 0;
  if (HAL_ADC_ConfigChannel(&hadc4, &sConfig) != HAL_OK)
  {
    Error_Handler();
  }

  /** Configure Regular Channel
  */
  sConfig.Channel = ADC_CHANNEL_8;
  sConfig.Rank = ADC4_REGULAR_RANK_2;
  if (HAL_ADC_ConfigChannel(&hadc4, &sConfig) != HAL_OK)
  {
    Error_Handler();
  }

}

static void MX_DMA2D_Init(void)
{

  hdma2d.Instance = DMA2D;
  hdma2d.Init.Mode = DMA2D_M2M;
  hdma2d.Init.ColorMode = DMA2D_OUTPUT_RGB888;
  hdma2d.Init.OutputOffset = 0;
  hdma2d.Init.BytesSwap = DMA2D_BYTES_REGULAR;
  hdma2d.Init.LineOffsetMode = DMA2D_LOM_PIXELS;
  hdma2d.LayerCfg[1].InputOffset = 0;
  hdma2d.LayerCfg[1].InputColorMode = DMA2D_INPUT_RGB888;
  hdma2d.LayerCfg[1].AlphaMode = DMA2D_NO_MODIF_ALPHA;
  hdma2d.LayerCfg[1].InputAlpha = 0;
  hdma2d.LayerCfg[1].AlphaInverted = DMA2D_REGULAR_ALPHA;
  hdma2d.LayerCfg[1].RedBlueSwap = DMA2D_RB_REGULAR;
  if (HAL_DMA2D_Init(&hdma2d) != HAL_OK)
  {
    Error_Handler();
  }
  if (HAL_DMA2D_ConfigLayer(&hdma2d, 1) != HAL_OK)
  {
    Error_Handler();
  }

}

static void MX_GPDMA1_Init(void)
{

  /* Peripheral clock enable */
  __HAL_RCC_GPDMA1_CLK_ENABLE();

  /* GPDMA1 interrupt Init */
    HAL_NVIC_SetPriority(GPDMA1_Channel0_IRQn, 0, 0);
    HAL_NVIC_EnableIRQ(GPDMA1_Channel0_IRQn);
    HAL_NVIC_SetPriority(GPDMA1_Channel1_IRQn, 0, 0);
    HAL_NVIC_EnableIRQ(GPDMA1_Channel1_IRQn);
    HAL_NVIC_SetPriority(GPDMA1_Channel2_IRQn, 0, 0);
    HAL_NVIC_EnableIRQ(GPDMA1_Channel2_IRQn);
    HAL_NVIC_SetPriority(GPDMA1_Channel3_IRQn, 0, 0);
    HAL_NVIC_EnableIRQ(GPDMA1_Channel3_IRQn);

}

static void MX_HSPI1_Init(void)
{

  /* HSPI1 parameter configuration*/
  hxspi1.Instance = HSPI1;
  hxspi1.Init.FifoThresholdByte = 4;
  hxspi1.Init.MemoryMode = HAL_XSPI_SINGLE_MEM;
  hxspi1.Init.MemoryType = HAL_XSPI_MEMTYPE_MACRONIX;
  hxspi1.Init.MemorySize = HAL_XSPI_SIZE_1GB;
  hxspi1.Init.ChipSelectHighTimeCycle = 2;
  hxspi1.Init.FreeRunningClock = HAL_XSPI_FREERUNCLK_DISABLE;
  hxspi1.Init.ClockMode = HAL_XSPI_CLOCK_MODE_0;
  hxspi1.Init.WrapSize = HAL_XSPI_WRAP_NOT_SUPPORTED;
  hxspi1.Init.ClockPrescaler = 0;
  hxspi1.Init.SampleShifting = HAL_XSPI_SAMPLE_SHIFT_NONE;
  hxspi1.Init.DelayHoldQuarterCycle = HAL_XSPI_DHQC_DISABLE;
  hxspi1.Init.ChipSelectBoundary = HAL_XSPI_BONDARYOF_NONE;
  hxspi1.Init.MaxTran = 0;
  hxspi1.Init.Refresh = 0;
  if (HAL_XSPI_Init(&hxspi1) != HAL_OK)
  {
    Error_Handler();
  }

}

static void MX_I2C1_Init(void)
{

  hi2c1.Instance = I2C1;
  hi2c1.Init.Timing = 0x20A0C4DF;
  hi2c1.Init.OwnAddress1 = 0;
  hi2c1.Init.AddressingMode = I2C_ADDRESSINGMODE_7BIT;
  hi2c1.Init.DualAddressMode = I2C_DUALADDRESS_DISABLE;
  hi2c1.Init.OwnAddress2 = 0;
  hi2c1.Init.OwnAddress2Masks = I2C_OA2_NOMASK;
  hi2c1.Init.GeneralCallMode = I2C_GENERALCALL_DISABLE;
  hi2c1.Init.NoStretchMode = I2C_NOSTRETCH_DISABLE;
  if (HAL_I2C_Init(&hi2c1) != HAL_OK)
  {
    Error_Handler();
  }

  /** Configure Analogue filter
  */
  if (HAL_I2CEx_ConfigAnalogFilter(&hi2c1, I2C_ANALOGFILTER_ENABLE) != HAL_OK)
  {
    Error_Handler();
  }

  /** Configure Digital filter
  */
  if (HAL_I2CEx_ConfigDigitalFilter(&hi2c1, 0) != HAL_OK)
  {
    Error_Handler();
  }

}

static void MX_I2C2_Init(void)
{

  hi2c2.Instance = I2C2;
  hi2c2.Init.Timing = 0x20A0C4DF;
  hi2c2.Init.OwnAddress1 = 0;
  hi2c2.Init.AddressingMode = I2C_ADDRESSINGMODE_7BIT;
  hi2c2.Init.DualAddressMode = I2C_DUALADDRESS_DISABLE;
  hi2c2.Init.OwnAddress2 = 0;
  hi2c2.Init.OwnAddress2Masks = I2C_OA2_NOMASK;
  hi2c2.Init.GeneralCallMode = I2C_GENERALCALL_DISABLE;
  hi2c2.Init.NoStretchMode = I2C_NOSTRETCH_DISABLE;
  if (HAL_I2C_Init(&hi2c2) != HAL_OK)
  {
    Error_Handler();
  }

  /** Configure Analogue filter
  */
  if (HAL_I2CEx_ConfigAnalogFilter(&hi2c2, I2C_ANALOGFILTER_ENABLE) != HAL_OK)
  {
    Error_Handler();
  }

  /** Configure Digital filter
  */
  if (HAL_I2CEx_ConfigDigitalFilter(&hi2c2, 0) != HAL_OK)
  {
    Error_Handler();
  }

}

static void MX_ICACHE_Init(void)
{

  /** Enable instruction cache in 1-way (direct mapped cache)
  */
  if (HAL_ICACHE_ConfigAssociativityMode(ICACHE_1WAY) != HAL_OK)
  {
    Error_Handler();
  }
  if (HAL_ICACHE_Enable() != HAL_OK)
  {
    Error_Handler();
  }

}

static void MX_LTDC_Init(void)
{

  LTDC_LayerCfgTypeDef pLayerCfg = {0};

  hltdc.Instance = LTDC;
  hltdc.Init.HSPolarity = LTDC_HSPOLARITY_AL;
  hltdc.Init.VSPolarity = LTDC_VSPOLARITY_AL;
  hltdc.Init.DEPolarity = LTDC_DEPOLARITY_AL;
  hltdc.Init.PCPolarity = LTDC_PCPOLARITY_IPC;
  hltdc.Init.HorizontalSync = 3;
  hltdc.Init.VerticalSync = 3;
  hltdc.Init.AccumulatedHBP = 11;
  hltdc.Init.AccumulatedVBP = 11;
  hltdc.Init.AccumulatedActiveW = 811;
  hltdc.Init.AccumulatedActiveH = 491;
  hltdc.Init.TotalWidth = 819;
  hltdc.Init.TotalHeigh = 499;
  hltdc.Init.Backcolor.Blue = 0;
  hltdc.Init.Backcolor.Green = 0;
  hltdc.Init.Backcolor.Red = 0;
  if (HAL_LTDC_Init(&hltdc) != HAL_OK)
  {
    Error_Handler();
  }
  pLayerCfg.WindowX0 = 0;
  pLayerCfg.WindowX1 = 800;
  pLayerCfg.WindowY0 = 0;
  pLayerCfg.WindowY1 = 480;
  pLayerCfg.PixelFormat = LTDC_PIXEL_FORMAT_RGB888;
  pLayerCfg.Alpha = 255;
  pLayerCfg.Alpha0 = 0;
  pLayerCfg.BlendingFactor1 = LTDC_BLENDING_FACTOR1_PAxCA;
  pLayerCfg.BlendingFactor2 = LTDC_BLENDING_FACTOR2_PAxCA;
  pLayerCfg.FBStartAdress = 0;
  pLayerCfg.ImageWidth = 0;
  pLayerCfg.ImageHeight = 0;
  pLayerCfg.Backcolor.Blue = 0;
  pLayerCfg.Backcolor.Green = 0;
  pLayerCfg.Backcolor.Red = 0;
  if (HAL_LTDC_ConfigLayer(&hltdc, &pLayerCfg, 0) != HAL_OK)
  {
    Error_Handler();
  }

}

static void MX_RTC_Init(void)
{

  RTC_PrivilegeStateTypeDef privilegeState = {0};

  /** Initialize RTC Only
  */
  hrtc.Instance = RTC;
  hrtc.Init.HourFormat = RTC_HOURFORMAT_24;
  hrtc.Init.AsynchPrediv = 127;
  hrtc.Init.SynchPrediv = 255;
  hrtc.Init.OutPut = RTC_OUTPUT_DISABLE;
  hrtc.Init.OutPutRemap = RTC_OUTPUT_REMAP_NONE;
  hrtc.Init.OutPutPolarity = RTC_OUTPUT_POLARITY_HIGH;
  hrtc.Init.OutPutType = RTC_OUTPUT_TYPE_OPENDRAIN;
  hrtc.Init.OutPutPullUp = RTC_OUTPUT_PULLUP_NONE;
  hrtc.Init.BinMode = RTC_BINARY_NONE;
  if (HAL_RTC_Init(&hrtc) != HAL_OK)
  {
    Error_Handler();
  }
  privilegeState.rtcPrivilegeFull = RTC_PRIVILEGE_FULL_NO;
  privilegeState.backupRegisterPrivZone = RTC_PRIVILEGE_BKUP_ZONE_NONE;
  privilegeState.backupRegisterStartZone2 = RTC_BKP_DR0;
  privilegeState.backupRegisterStartZone3 = RTC_BKP_DR0;
  if (HAL_RTCEx_PrivilegeModeSet(&hrtc, &privilegeState) != HAL_OK)
  {
    Error_Handler();
  }

}

static void MX_SAI2_Init(void)
{

  hsai_BlockA2.Instance = SAI2_Block_A;
  hsai_BlockA2.Init.AudioMode = SAI_MODEMASTER_TX;
  hsai_BlockA2.Init.Synchro = SAI_ASYNCHRONOUS;
  hsai_BlockA2.Init.OutputDrive = SAI_OUTPUTDRIVE_DISABLE;
  hsai_BlockA2.Init.NoDivider = SAI_MASTERDIVIDER_ENABLE;
  hsai_BlockA2.Init.FIFOThreshold = SAI_FIFOTHRESHOLD_EMPTY;
  hsai_BlockA2.Init.AudioFrequency = SAI_AUDIO_FREQUENCY_96K;
  hsai_BlockA2.Init.SynchroExt = SAI_SYNCEXT_DISABLE;
  hsai_BlockA2.Init.MckOutput = SAI_MCK_OUTPUT_ENABLE;
  hsai_BlockA2.Init.MonoStereoMode = SAI_STEREOMODE;
  hsai_BlockA2.Init.CompandingMode = SAI_NOCOMPANDING;
  hsai_BlockA2.Init.TriState = SAI_OUTPUT_RELEASED;
  if (HAL_SAI_InitProtocol(&hsai_BlockA2, SAI_I2S_MSBJUSTIFIED, SAI_PROTOCOL_DATASIZE_24BIT, 2) != HAL_OK)
  {
    Error_Handler();
  }
  hsai_BlockB2.Instance = SAI2_Block_B;
  hsai_BlockB2.Init.AudioMode = SAI_MODEMASTER_RX;
  hsai_BlockB2.Init.Synchro = SAI_ASYNCHRONOUS;
  hsai_BlockB2.Init.OutputDrive = SAI_OUTPUTDRIVE_DISABLE;
  hsai_BlockB2.Init.NoDivider = SAI_MASTERDIVIDER_ENABLE;
  hsai_BlockB2.Init.FIFOThreshold = SAI_FIFOTHRESHOLD_HF;
  hsai_BlockB2.Init.AudioFrequency = SAI_AUDIO_FREQUENCY_96K;
  hsai_BlockB2.Init.SynchroExt = SAI_SYNCEXT_DISABLE;
  hsai_BlockB2.Init.MckOutput = SAI_MCK_OUTPUT_ENABLE;
  hsai_BlockB2.Init.MonoStereoMode = SAI_STEREOMODE;
  hsai_BlockB2.Init.CompandingMode = SAI_NOCOMPANDING;
  if (HAL_SAI_InitProtocol(&hsai_BlockB2, SAI_I2S_STANDARD, SAI_PROTOCOL_DATASIZE_24BIT, 8) != HAL_OK)
  {
    Error_Handler();
  }

}

static void MX_TIM3_Init(void)
{

  TIM_MasterConfigTypeDef sMasterConfig = {0};
  TIM_OC_InitTypeDef sConfigOC = {0};

  htim3.Instance = TIM3;
  htim3.Init.Prescaler = 160;
  htim3.Init.CounterMode = TIM_COUNTERMODE_UP;
  htim3.Init.Period = 100;
  htim3.Init.ClockDivision = TIM_CLOCKDIVISION_DIV1;
  htim3.Init.AutoReloadPreload = TIM_AUTORELOAD_PRELOAD_DISABLE;
  if (HAL_TIM_PWM_Init(&htim3) != HAL_OK)
  {
    Error_Handler();
  }
  sMasterConfig.MasterOutputTrigger = TIM_TRGO_RESET;
  sMasterConfig.MasterSlaveMode = TIM_MASTERSLAVEMODE_DISABLE;
  if (HAL_TIMEx_MasterConfigSynchronization(&htim3, &sMasterConfig) != HAL_OK)
  {
    Error_Handler();
  }
  sConfigOC.OCMode = TIM_OCMODE_PWM1;
  sConfigOC.Pulse = 75;
  sConfigOC.OCPolarity = TIM_OCPOLARITY_HIGH;
  sConfigOC.OCFastMode = TIM_OCFAST_DISABLE;
  if (HAL_TIM_PWM_ConfigChannel(&htim3, &sConfigOC, TIM_CHANNEL_4) != HAL_OK)
  {
    Error_Handler();
  }
  __HAL_TIM_DISABLE_OCxPRELOAD(&htim3, TIM_CHANNEL_4);
  HAL_TIM_MspPostInit(&htim3);

}

static void MX_TIM15_Init(void)
{

  TIM_ClockConfigTypeDef sClockSourceConfig = {0};
  TIM_MasterConfigTypeDef sMasterConfig = {0};

  htim15.Instance = TIM15;
  htim15.Init.Prescaler = 26;
  htim15.Init.CounterMode = TIM_COUNTERMODE_UP;
  htim15.Init.Period = 49;
  htim15.Init.ClockDivision = TIM_CLOCKDIVISION_DIV1;
  htim15.Init.RepetitionCounter = 0;
  htim15.Init.AutoReloadPreload = TIM_AUTORELOAD_PRELOAD_DISABLE;
  if (HAL_TIM_Base_Init(&htim15) != HAL_OK)
  {
    Error_Handler();
  }
  sClockSourceConfig.ClockSource = TIM_CLOCKSOURCE_INTERNAL;
  if (HAL_TIM_ConfigClockSource(&htim15, &sClockSourceConfig) != HAL_OK)
  {
    Error_Handler();
  }
  sMasterConfig.MasterOutputTrigger = TIM_TRGO_UPDATE;
  sMasterConfig.MasterSlaveMode = TIM_MASTERSLAVEMODE_DISABLE;
  if (HAL_TIMEx_MasterConfigSynchronization(&htim15, &sMasterConfig) != HAL_OK)
  {
    Error_Handler();
  }

}

static void MX_USART1_UART_Init(void)
{

  huart1.Instance = USART1;
  huart1.Init.BaudRate = 115200;
  huart1.Init.WordLength = UART_WORDLENGTH_8B;
  huart1.Init.StopBits = UART_STOPBITS_1;
  huart1.Init.Parity = UART_PARITY_NONE;
  huart1.Init.Mode = UART_MODE_TX_RX;
  huart1.Init.HwFlowCtl = UART_HWCONTROL_NONE;
  huart1.Init.OverSampling = UART_OVERSAMPLING_16;
  huart1.Init.OneBitSampling = UART_ONE_BIT_SAMPLE_DISABLE;
  huart1.Init.ClockPrescaler = UART_PRESCALER_DIV1;
  huart1.AdvancedInit.AdvFeatureInit = UART_ADVFEATURE_NO_INIT;
  if (HAL_UART_Init(&huart1) != HAL_OK)
  {
    Error_Handler();
  }
  if (HAL_UARTEx_SetTxFifoThreshold(&huart1, UART_TXFIFO_THRESHOLD_1_8) != HAL_OK)
  {
    Error_Handler();
  }
  if (HAL_UARTEx_SetRxFifoThreshold(&huart1, UART_RXFIFO_THRESHOLD_1_8) != HAL_OK)
  {
    Error_Handler();
  }
  if (HAL_UARTEx_DisableFifoMode(&huart1) != HAL_OK)
  {
    Error_Handler();
  }

}

static void MX_USB_OTG_HS_PCD_Init(void)
{

  hpcd_USB_OTG_HS.Instance = USB_OTG_HS;
  hpcd_USB_OTG_HS.Init.dev_endpoints = 9;
  hpcd_USB_OTG_HS.Init.speed = PCD_SPEED_HIGH;
  hpcd_USB_OTG_HS.Init.phy_itface = USB_OTG_HS_EMBEDDED_PHY;
  hpcd_USB_OTG_HS.Init.Sof_enable = DISABLE;
  hpcd_USB_OTG_HS.Init.low_power_enable = DISABLE;
  hpcd_USB_OTG_HS.Init.lpm_enable = DISABLE;
  hpcd_USB_OTG_HS.Init.use_dedicated_ep1 = DISABLE;
  hpcd_USB_OTG_HS.Init.vbus_sensing_enable = DISABLE;
  hpcd_USB_OTG_HS.Init.dma_enable = DISABLE;
  if (HAL_PCD_Init(&hpcd_USB_OTG_HS) != HAL_OK)
  {
    Error_Handler();
  }

}

static void MX_GPIO_Init(void)
{
  GPIO_InitTypeDef GPIO_InitStruct = {0};

  /* GPIO Ports Clock Enable */
  __HAL_RCC_GPIOE_CLK_ENABLE();
  __HAL_RCC_GPIOC_CLK_ENABLE();
  __HAL_RCC_GPIOF_CLK_ENABLE();
  __HAL_RCC_GPIOH_CLK_ENABLE();
  __HAL_RCC_GPIOA_CLK_ENABLE();
  __HAL_RCC_GPIOB_CLK_ENABLE();
  __HAL_RCC_GPIOG_CLK_ENABLE();
  __HAL_RCC_GPIOD_CLK_ENABLE();
  __HAL_RCC_GPIOI_CLK_ENABLE();

  /*Configure GPIO pin Output Level */
  HAL_GPIO_WritePin(ADC_Power_On_GPIO_Port, ADC_Power_On_Pin, GPIO_PIN_RESET);

  /*Configure GPIO pin Output Level */
  HAL_GPIO_WritePin(LCD_ON_GPIO_Port, LCD_ON_Pin, GPIO_PIN_SET);

  /*Configure GPIO pin Output Level */
  HAL_GPIO_WritePin(GPIOD, RED_LED_Pin|GREEN_LED_Pin, GPIO_PIN_RESET);

  /*Configure GPIO pins : ADC_Power_On_Pin LCD_ON_Pin */
  GPIO_InitStruct.Pin = ADC_Power_On_Pin|LCD_ON_Pin;
  GPIO_InitStruct.Mode = GPIO_MODE_OUTPUT_PP;
  GPIO_InitStruct.Pull = GPIO_NOPULL;
  GPIO_InitStruct.Speed = GPIO_SPEED_FREQ_LOW;
  HAL_GPIO_Init(GPIOE, &GPIO_InitStruct);

  /*Configure GPIO pin : TP_IRQ_Pin */
  GPIO_InitStruct.Pin = TP_IRQ_Pin;
  GPIO_InitStruct.Mode = GPIO_MODE_IT_RISING;
  GPIO_InitStruct.Pull = GPIO_NOPULL;
  HAL_GPIO_Init(TP_IRQ_GPIO_Port, &GPIO_InitStruct);

  /*Configure GPIO pin : USB_DETECT_Pin */
  GPIO_InitStruct.Pin = USB_DETECT_Pin;
  GPIO_InitStruct.Mode = GPIO_MODE_IT_RISING_FALLING;
  GPIO_InitStruct.Pull = GPIO_NOPULL;
  HAL_GPIO_Init(USB_DETECT_GPIO_Port, &GPIO_InitStruct);

  /*Configure GPIO pin : USB_FAULT_Pin */
  GPIO_InitStruct.Pin = USB_FAULT_Pin;
  GPIO_InitStruct.Mode = GPIO_MODE_IT_FALLING;
  GPIO_InitStruct.Pull = GPIO_PULLUP;
  HAL_GPIO_Init(USB_FAULT_GPIO_Port, &GPIO_InitStruct);

  /*Configure GPIO pins : RED_LED_Pin GREEN_LED_Pin */
  GPIO_InitStruct.Pin = RED_LED_Pin|GREEN_LED_Pin;
  GPIO_InitStruct.Mode = GPIO_MODE_OUTPUT_PP;
  GPIO_InitStruct.Pull = GPIO_NOPULL;
  GPIO_InitStruct.Speed = GPIO_SPEED_FREQ_LOW;
  HAL_GPIO_Init(GPIOD, &GPIO_InitStruct);

  /*Configure GPIO pin : Master_Mute_Pin */
  GPIO_InitStruct.Pin = Master_Mute_Pin;
  GPIO_InitStruct.Mode = GPIO_MODE_INPUT;
  GPIO_InitStruct.Pull = GPIO_NOPULL;
  HAL_GPIO_Init(Master_Mute_GPIO_Port, &GPIO_InitStruct);

  /*Configure GPIO pins : Channel_6_Mute_Pin Channel_2_Mute_Pin Master_MuteG15_Pin */
  GPIO_InitStruct.Pin = Channel_6_Mute_Pin|Channel_2_Mute_Pin|Master_MuteG15_Pin;
  GPIO_InitStruct.Mode = GPIO_MODE_INPUT;
  GPIO_InitStruct.Pull = GPIO_NOPULL;
  HAL_GPIO_Init(GPIOG, &GPIO_InitStruct);

  /*Configure GPIO pins : Channel_5_Mute_Pin Channel_4_Mute_Pin Channel_3_Mute_Pin Channel_1_Mute_Pin */
  GPIO_InitStruct.Pin = Channel_5_Mute_Pin|Channel_4_Mute_Pin|Channel_3_Mute_Pin|Channel_1_Mute_Pin;
  GPIO_InitStruct.Mode = GPIO_MODE_INPUT;
  GPIO_InitStruct.Pull = GPIO_NOPULL;
  HAL_GPIO_Init(GPIOB, &GPIO_InitStruct);

  /* EXTI interrupt init*/
  HAL_NVIC_SetPriority(EXTI1_IRQn, 0, 0);
  HAL_NVIC_EnableIRQ(EXTI1_IRQn);

  HAL_NVIC_SetPriority(EXTI4_IRQn, 0, 0);
  HAL_NVIC_EnableIRQ(EXTI4_IRQn);

  HAL_NVIC_SetPriority(EXTI5_IRQn, 0, 0);
  HAL_NVIC_EnableIRQ(EXTI5_IRQn);

}

/* USER CODE BEGIN 4 */

void HAL_SAI_RxHalfCpltCallback(SAI_HandleTypeDef *hsai)
{
	ch1Vol = floor((((float)(adcGroup1[0] >> 6)) / 128.0f) * 100.0f) / 100.0f;
	uint16_t dacSlot = 0;
	for(int i = 4; i < (sampleSize * 8 ) / 2; i += 8)
	{
		float convert = ((((float)pcmData[i] * (float)gain) / 16777216.0f) - 0.5f) * 2.0f;
		int32_t output = (int32_t)(convert * 8388608);

		dacData[dacSlot] = output;
		dacData[dacSlot + 1] = output;
		dacSlot += 2;
	}
}

void HAL_SAI_RxCpltCallback(SAI_HandleTypeDef *hsai)
{
	ch1Vol = floor((((float)(adcGroup1[0] >> 6)) / 128.0f) * 100.0f) / 100.0f;
	uint16_t dacSlot = sampleSize;
	for(int i = ((sampleSize * 8) / 2) + 4; i < sampleSize * 8; i += 8)
	{
		float convert = ((((float)pcmData[i] * (float)gain) / 16777216.0f) - 0.5f) * 2.0f;
		int32_t output = (int32_t)(convert * 8388608);

		dacData[dacSlot] = output;
		dacData[dacSlot + 1] = output;
		dacSlot += 2;
	}
}
/* USER CODE END 4 */

void Error_Handler(void)
{
  __disable_irq();
  while (1)
  {
  }
}
